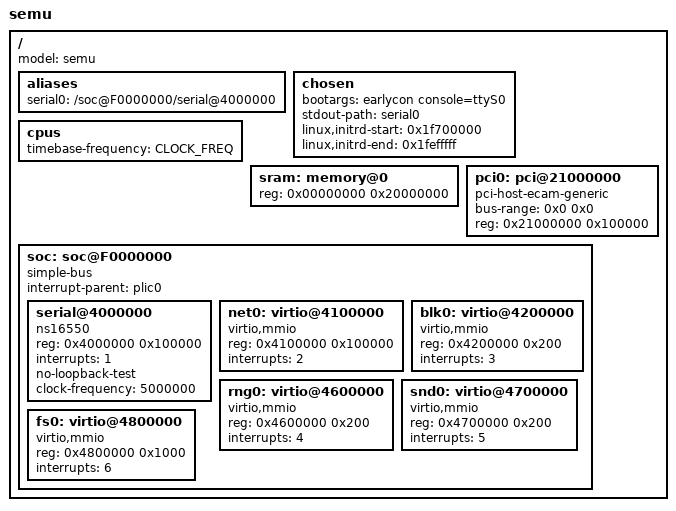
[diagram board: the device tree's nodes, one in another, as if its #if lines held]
/dts-v1/;

/*
 * RISC-V harts descriptions
 */ 
#include "riscv-harts.dtsi"

/ {
    #address-cells = <1>;
    #size-cells = <1>;
    model = "semu";

    aliases {
        serial0 = "/soc@F0000000/serial@4000000";
    };

    chosen {
        bootargs = "earlycon console=ttyS0";
        stdout-path = "serial0";
        linux,initrd-start = <0x1f700000>; /* @403 MiB (503 * 1024 * 1024)     */
        linux,initrd-end = <0x1fefffff>;   /* @511 MiB (511 * 1024 * 1024 - 1) */
    };

    cpus {
        #address-cells = <1>;
        #size-cells = <0>;
        timebase-frequency = <CLOCK_FREQ>;
    };

    sram: memory@0 {
        device_type = "memory";
        reg = <0x00000000 0x20000000>;
        reg-names = "sram0";
    };

#if SEMU_FEATURE_VIRTIOPCI
    pci0: pci@21000000 {
        compatible = "pci-host-ecam-generic";
        device_type = "pci";
        #address-cells = <3>;
        #size-cells = <2>;
        bus-range = <0x0 0x0>; /* Use 1 bus only */
        reg = <0x21000000 0x100000>;

        /* Reserve memory for BAR mapping */
        ranges = <0x02000000 0 0x100000   /* PCI memory space (BAR) */
                  0x20000000 0 0x100000>; /* CPU address space, 16MB */
    };
#endif

    soc: soc@F0000000 {
        #address-cells = <1>;
        #size-cells = <1>;
        compatible = "simple-bus";
        ranges = <0x0 0xF0000000 0x10000000>;
        interrupt-parent = <&plic0>;

        serial@4000000 {
            compatible = "ns16550";
            reg = <0x4000000 0x100000>;
            interrupts = <1>;
            no-loopback-test;
            clock-frequency = <5000000>; /* the baudrate divisor is ignored */
        };

#if SEMU_FEATURE_VIRTIONET
        net0: virtio@4100000 {
            compatible = "virtio,mmio";
            reg = <0x4100000 0x100000>;
            interrupts = <2>;
        };
#endif

#if SEMU_FEATURE_VIRTIOBLK
        blk0: virtio@4200000 {
            compatible = "virtio,mmio";
            reg = <0x4200000 0x200>;
            interrupts = <3>;
        };
#endif

#if SEMU_FEATURE_VIRTIORNG
        rng0: virtio@4600000 {
            compatible = "virtio,mmio";
            reg = <0x4600000 0x200>;
            interrupts = <4>;
        };
#endif

#if SEMU_FEATURE_VIRTIOSND
        snd0: virtio@4700000 {
            compatible = "virtio,mmio";
            reg = <0x4700000 0x200>;
            interrupts = <5>;
        };
#endif

#if SEMU_FEATURE_VIRTIOFS
        fs0: virtio@4800000 {
            compatible = "virtio,mmio";
            reg = <0x4800000 0x1000>;
            interrupts = <6>;
        };
#endif
    };
};
